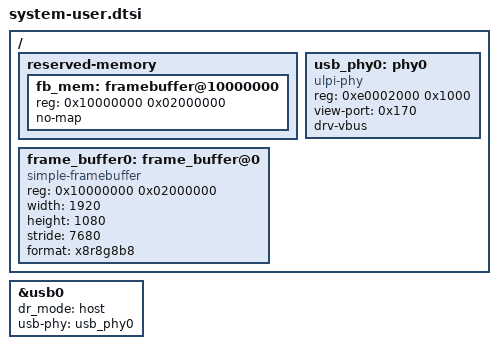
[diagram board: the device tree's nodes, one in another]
/include/ "system-conf.dtsi"
/ {
	reserved-memory {
		#address-cells = <1>;
		#size-cells = <1>;
		ranges;

		fb_mem: framebuffer@10000000 {
		    reg = <0x10000000 0x02000000>;  /* same as your framebuffer */
		    no-map;
		};
	};

	frame_buffer0: frame_buffer@0 {                      
	    compatible = "simple-framebuffer";
	    reg = <0x10000000 0x02000000>;
	    width = <1920>;
	    height = <1080>;
	    stride = <7680>;
	    format = "x8r8g8b8";
	    status = "okay";
	};

	usb_phy0: phy0 {
	    compatible = "ulpi-phy";
	    #phy-cells = <0>;
	    reg = <0xe0002000 0x1000>;
	    view-port = <0x170>;
	    drv-vbus;
	};
};

&usb0{
    dr_mode = "host";
    usb-phy = <&usb_phy0>;
};
